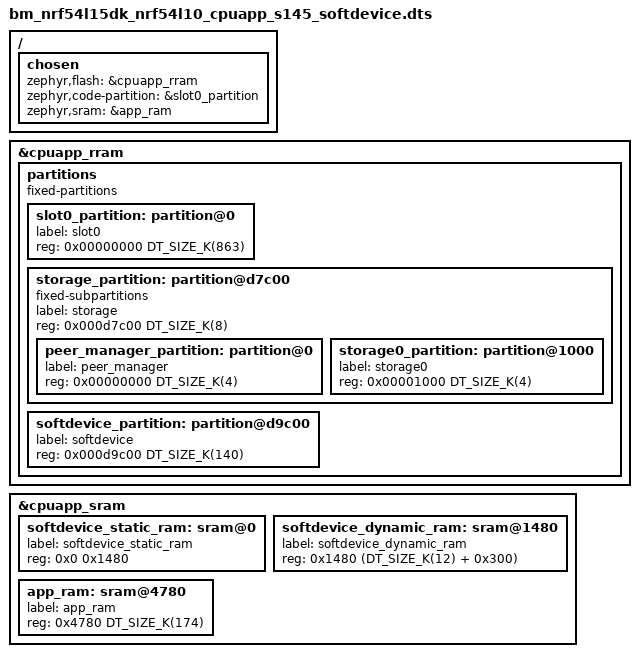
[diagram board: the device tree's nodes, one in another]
/*
 * Copyright (c) 2025 Nordic Semiconductor ASA
 *
 * SPDX-License-Identifier: LicenseRef-Nordic-5-Clause
 */

/dts-v1/;

#include <nordic/nrf54l10_cpuapp.dtsi>
#include "bm_nrf54l15dk_nrf54l10_cpuapp_common.dtsi"

/ {
	chosen {
		zephyr,flash = &cpuapp_rram;
		zephyr,code-partition = &slot0_partition;
		zephyr,sram = &app_ram;
	};
};

&cpuapp_rram {
	status = "okay";

	partitions {
		compatible = "fixed-partitions";
		#address-cells = <1>;
		#size-cells = <1>;

		slot0_partition: partition@0 {
			label = "slot0";
			reg = <0x00000000 DT_SIZE_K(863)>;
		};

		storage_partition: partition@d7c00 {
			compatible = "fixed-subpartitions";
			label = "storage";
			reg = <0x000d7c00 DT_SIZE_K(8)>;
			ranges = <0x0 0xd7c00 DT_SIZE_K(8)>;
			#address-cells = <1>;
			#size-cells = <1>;

			peer_manager_partition: partition@0 {
				label = "peer_manager";
				reg = <0x00000000 DT_SIZE_K(4)>;
			};

			storage0_partition: partition@1000 {
				label = "storage0";
				reg = <0x00001000 DT_SIZE_K(4)>;
			};
		};

		softdevice_partition: partition@d9c00 {
			label = "softdevice";
			reg = <0x000d9c00 DT_SIZE_K(140)>;
		};
	};
};

&cpuapp_sram {
	status = "okay";

	softdevice_static_ram: sram@0 {
		label = "softdevice_static_ram";
		reg = <0x0 0x1480>;
	};

	softdevice_dynamic_ram: sram@1480 {
		label = "softdevice_dynamic_ram";
		reg = <0x1480 (DT_SIZE_K(12) + 0x300)>;
	};

	app_ram: sram@4780 {
		label = "app_ram";
		reg = <0x4780 DT_SIZE_K(174)>;
	};
};
